AUTOSAR XML (schema 4-0-3)
standard types defined: Boolean, UInt16, UInt32
package /AUTOSAR_Platform/DataConstrs
  range DC_Boolean: raw 0..1
  range DC_UInt16: raw 0..65535
package /PATAC/Facility/DataTypes/Implementation
  compu method COMPU_Boolean: 0=FALSE, 1=TRUE
  unit NoUnit: factor-si-to-unit=1, offset-si-to-unit=0
package /PATAC/MSM/ComponentTypes
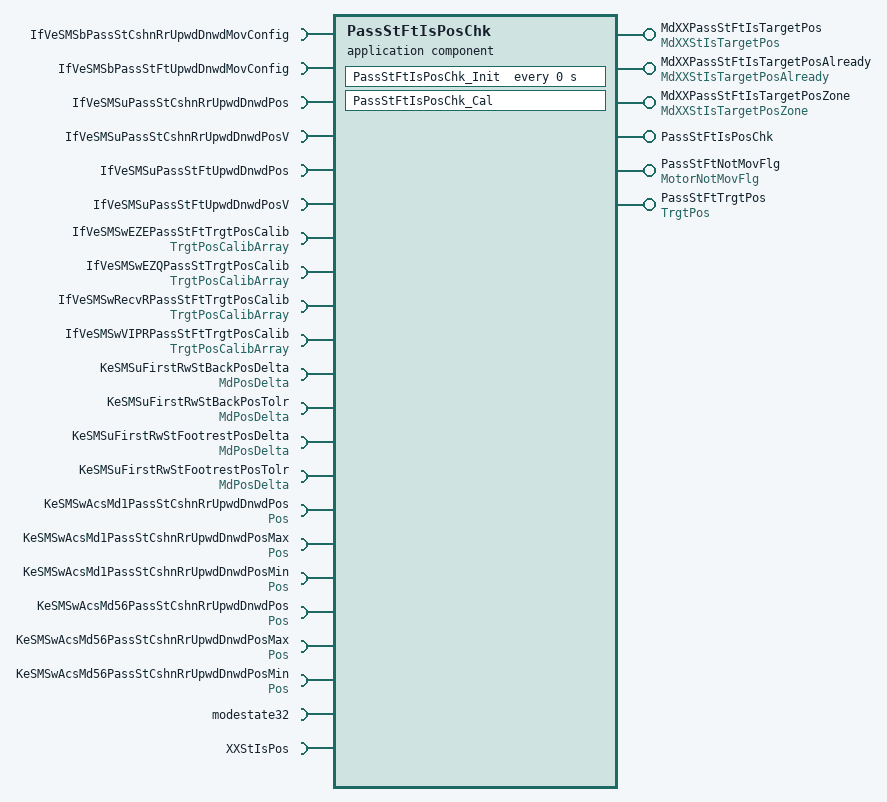
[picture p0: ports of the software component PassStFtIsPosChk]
  application sw component type PassStFtIsPosChk
    6 x provide port:
      MdXXPassStFtIsTargetPos: nonqueued-sender-com-spec{data-element=MdXXStIsTargetPos/Val, init-value=0}, provided-interface=MdXXStIsTargetPos
      MdXXPassStFtIsTargetPosAlready: nonqueued-sender-com-spec{data-element=MdXXStIsTargetPosAlready/Val, init-value=0}, provided-interface=MdXXStIsTargetPosAlready
      MdXXPassStFtIsTargetPosZone: nonqueued-sender-com-spec=data-element=MdXXStIsTargetPosZone/Val, provided-interface=MdXXStIsTargetPosZone
      PassStFtIsPosChk: server-com-spec{operation=Cal, queue-length=1}, provided-interface=PassStFtIsPosChk
      PassStFtNotMovFlg: nonqueued-sender-com-spec{data-element=MotorNotMovFlg/Val, init-value=0}, provided-interface=MotorNotMovFlg
      PassStFtTrgtPos: nonqueued-sender-com-spec{data-element=TrgtPos/Val, init-value=4095}, provided-interface=TrgtPos
    22 x require port:
      IfVeSMSbPassStCshnRrUpwdDnwdMovConfig: nonqueued-receiver-com-spec{data-element=IfVeSMSbPassStCshnRrUpwdDnwdMovConfig/Val, filter=data-filter-type=ALWAYS}, required-interface=IfVeSMSbPassStCshnRrUpwdDnwdMovConfig
      IfVeSMSbPassStFtUpwdDnwdMovConfig: nonqueued-receiver-com-spec{data-element=IfVeSMSbPassStFtUpwdDnwdMovConfig/Val, filter=data-filter-type=ALWAYS, init-value=0}, required-interface=IfVeSMSbPassStFtUpwdDnwdMovConfig
      IfVeSMSuPassStCshnRrUpwdDnwdPos: nonqueued-receiver-com-spec{data-element=IfVeSMSuPassStCshnRrUpwdDnwdPos/Val, filter=data-filter-type=ALWAYS}, required-interface=IfVeSMSuPassStCshnRrUpwdDnwdPos
      IfVeSMSuPassStCshnRrUpwdDnwdPosV: nonqueued-receiver-com-spec{data-element=IfVeSMSuPassStCshnRrUpwdDnwdPosV/Val, filter=data-filter-type=ALWAYS}, required-interface=IfVeSMSuPassStCshnRrUpwdDnwdPosV
      IfVeSMSuPassStFtUpwdDnwdPos: nonqueued-receiver-com-spec{data-element=IfVeSMSuPassStFtUpwdDnwdPos/Val, filter=data-filter-type=ALWAYS, init-value=0}, required-interface=IfVeSMSuPassStFtUpwdDnwdPos
      IfVeSMSuPassStFtUpwdDnwdPosV: nonqueued-receiver-com-spec{data-element=IfVeSMSuPassStFtUpwdDnwdPosV/Val, filter=data-filter-type=ALWAYS, init-value=0}, required-interface=IfVeSMSuPassStFtUpwdDnwdPosV
      IfVeSMSwEZEPassStFtTrgtPosCalib: nonqueued-receiver-com-spec{data-element=TrgtPosArray, filter=data-filter-type=ALWAYS, init-value=[4095, 4095, 4095]}, required-interface=TrgtPosCalibArray
      IfVeSMSwEZQPassStTrgtPosCalib: nonqueued-receiver-com-spec{data-element=TrgtPosArray, filter=data-filter-type=ALWAYS, init-value=[4095, 4095, 4095]}, required-interface=TrgtPosCalibArray
      IfVeSMSwRecvRPassStFtTrgtPosCalib: nonqueued-receiver-com-spec{data-element=TrgtPosArray, filter=data-filter-type=ALWAYS, init-value=[4095, 4095, 4095]}, required-interface=TrgtPosCalibArray
      IfVeSMSwVIPRPassStFtTrgtPosCalib: nonqueued-receiver-com-spec{data-element=TrgtPosArray, filter=data-filter-type=ALWAYS, init-value=[4095, 4095, 4095]}, required-interface=TrgtPosCalibArray
      KeSMSuFirstRwStBackPosDelta: parameter-require-com-spec{init-value=150, parameter=MdPosDelta/Val}, required-interface=MdPosDelta
      KeSMSuFirstRwStBackPosTolr: parameter-require-com-spec{init-value=150, parameter=MdPosDelta/Val}, required-interface=MdPosDelta
      KeSMSuFirstRwStFootrestPosDelta: parameter-require-com-spec{init-value=150, parameter=MdPosDelta/Val}, required-interface=MdPosDelta
      KeSMSuFirstRwStFootrestPosTolr: parameter-require-com-spec{init-value=150, parameter=MdPosDelta/Val}, required-interface=MdPosDelta
      KeSMSwAcsMd1PassStCshnRrUpwdDnwdPos: parameter-require-com-spec{init-value=0, parameter=Pos/Val}, required-interface=Pos
      KeSMSwAcsMd1PassStCshnRrUpwdDnwdPosMax: parameter-require-com-spec{init-value=0, parameter=Pos/Val}, required-interface=Pos
      KeSMSwAcsMd1PassStCshnRrUpwdDnwdPosMin: parameter-require-com-spec{init-value=0, parameter=Pos/Val}, required-interface=Pos
      KeSMSwAcsMd56PassStCshnRrUpwdDnwdPos: parameter-require-com-spec{init-value=0, parameter=Pos/Val}, required-interface=Pos
      KeSMSwAcsMd56PassStCshnRrUpwdDnwdPosMax: parameter-require-com-spec{init-value=0, parameter=Pos/Val}, required-interface=Pos
      KeSMSwAcsMd56PassStCshnRrUpwdDnwdPosMin: parameter-require-com-spec{init-value=0, parameter=Pos/Val}, required-interface=Pos
      modestate32: nonqueued-receiver-com-spec{data-element=modestate32/Val, filter=data-filter-type=ALWAYS, init-value=0}, required-interface=modestate32
      XXStIsPos: client-com-spec=Get, required-interface=XXStIsPos
    behavior PassStFtIsPosChk_InternalBehavior
      operation invoked event OIT_PassStFtIsPosChk_Cal_PassStFtIsPosChk_Cal: start-on-event=PassStFtIsPosChk_Cal, operation=PassStFtIsPosChk.Cal
      timing event PassStFtIsPosChk_InitEvent: start-on-event=PassStFtIsPosChk_Init, period=0
      runnable PassStFtIsPosChk_Cal
        data-receive-point-by-arguments:
          11 x access:
            REC_IfVeSMSbPassStCshnRrUpwdDnwdMovConfig_Val: accessed-variable=IfVeSMSbPassStCshnRrUpwdDnwdMovConfig.Val
            REC_IfVeSMSbPassStFtUpwdDnwdMovConfig_Val: accessed-variable=IfVeSMSbPassStFtUpwdDnwdMovConfig.Val
            REC_IfVeSMSuPassStCshnRrUpwdDnwdPos_Val: accessed-variable=IfVeSMSuPassStCshnRrUpwdDnwdPos.Val
            REC_IfVeSMSuPassStCshnRrUpwdDnwdPosV_Val: accessed-variable=IfVeSMSuPassStCshnRrUpwdDnwdPosV.Val
            REC_IfVeSMSuPassStFtUpwdDnwdPos_Val: accessed-variable=IfVeSMSuPassStFtUpwdDnwdPos.Val
            REC_IfVeSMSuPassStFtUpwdDnwdPosV_Val: accessed-variable=IfVeSMSuPassStFtUpwdDnwdPosV.Val
            REC_IfVeSMSwEZEPassStFtTrgtPosCalib_TrgtPosArray: accessed-variable=IfVeSMSwEZEPassStFtTrgtPosCalib.TrgtPosArray
            REC_IfVeSMSwEZQPassStTrgtPosCalib_TrgtPosArray: accessed-variable=IfVeSMSwEZQPassStTrgtPosCalib.TrgtPosArray
            REC_IfVeSMSwRecvRPassStFtTrgtPosCalib_TrgtPosArray: accessed-variable=IfVeSMSwRecvRPassStFtTrgtPosCalib.TrgtPosArray
            REC_IfVeSMSwVIPRPassStFtTrgtPosCalib_TrgtPosArray: accessed-variable=IfVeSMSwVIPRPassStFtTrgtPosCalib.TrgtPosArray
            REC_modestate32_Val: accessed-variable=modestate32.Val
        data-send-points:
          5 x access:
            SEND_MdXXPassStFtIsTargetPos_Val: accessed-variable=MdXXPassStFtIsTargetPos.Val
            SEND_MdXXPassStFtIsTargetPosAlready_Val: accessed-variable=MdXXPassStFtIsTargetPosAlready.Val
            SEND_MdXXPassStFtIsTargetPosZone_Val: accessed-variable=MdXXPassStFtIsTargetPosZone.Val
            SEND_PassStFtNotMovFlg_Val: accessed-variable=PassStFtNotMovFlg.Val
            SEND_PassStFtTrgtPos_Val: accessed-variable=PassStFtTrgtPos.Val
        10 x parameter access:
          PA_KeSMSuFirstRwStBackPosDelta_Val: accessed-parameter=KeSMSuFirstRwStBackPosDelta.Val
          PA_KeSMSuFirstRwStBackPosTolr_Val: accessed-parameter=KeSMSuFirstRwStBackPosTolr.Val
          PA_KeSMSuFirstRwStFootrestPosDelta_Val: accessed-parameter=KeSMSuFirstRwStFootrestPosDelta.Val
          PA_KeSMSuFirstRwStFootrestPosTolr_Val: accessed-parameter=KeSMSuFirstRwStFootrestPosTolr.Val
          PA_KeSMSwAcsMd1PassStCshnRrUpwdDnwdPos_Val: accessed-parameter=KeSMSwAcsMd1PassStCshnRrUpwdDnwdPos.Val
          PA_KeSMSwAcsMd1PassStCshnRrUpwdDnwdPosMax_Val: accessed-parameter=KeSMSwAcsMd1PassStCshnRrUpwdDnwdPosMax.Val
          PA_KeSMSwAcsMd1PassStCshnRrUpwdDnwdPosMin_Val: accessed-parameter=KeSMSwAcsMd1PassStCshnRrUpwdDnwdPosMin.Val
          PA_KeSMSwAcsMd56PassStCshnRrUpwdDnwdPos_Val: accessed-parameter=KeSMSwAcsMd56PassStCshnRrUpwdDnwdPos.Val
          PA_KeSMSwAcsMd56PassStCshnRrUpwdDnwdPosMax_Val: accessed-parameter=KeSMSwAcsMd56PassStCshnRrUpwdDnwdPosMax.Val
          PA_KeSMSwAcsMd56PassStCshnRrUpwdDnwdPosMin_Val: accessed-parameter=KeSMSwAcsMd56PassStCshnRrUpwdDnwdPosMin.Val
        sync call SC_XXStIsPos_Get: operation=XXStIsPos.Get, timeout=0
      runnable PassStFtIsPosChk_Init
        10 x parameter access:
          PA_KeSMSuFirstRwStBackPosDelta_Val: accessed-parameter=KeSMSuFirstRwStBackPosDelta.Val
          PA_KeSMSuFirstRwStBackPosTolr_Val: accessed-parameter=KeSMSuFirstRwStBackPosTolr.Val
          PA_KeSMSuFirstRwStFootrestPosDelta_Val: accessed-parameter=KeSMSuFirstRwStFootrestPosDelta.Val
          PA_KeSMSuFirstRwStFootrestPosTolr_Val: accessed-parameter=KeSMSuFirstRwStFootrestPosTolr.Val
          PA_KeSMSwAcsMd1PassStCshnRrUpwdDnwdPos_Val: accessed-parameter=KeSMSwAcsMd1PassStCshnRrUpwdDnwdPos.Val
          PA_KeSMSwAcsMd1PassStCshnRrUpwdDnwdPosMax_Val: accessed-parameter=KeSMSwAcsMd1PassStCshnRrUpwdDnwdPosMax.Val
          PA_KeSMSwAcsMd1PassStCshnRrUpwdDnwdPosMin_Val: accessed-parameter=KeSMSwAcsMd1PassStCshnRrUpwdDnwdPosMin.Val
          PA_KeSMSwAcsMd56PassStCshnRrUpwdDnwdPos_Val: accessed-parameter=KeSMSwAcsMd56PassStCshnRrUpwdDnwdPos.Val
          PA_KeSMSwAcsMd56PassStCshnRrUpwdDnwdPosMax_Val: accessed-parameter=KeSMSwAcsMd56PassStCshnRrUpwdDnwdPosMax.Val
          PA_KeSMSwAcsMd56PassStCshnRrUpwdDnwdPosMin_Val: accessed-parameter=KeSMSwAcsMd56PassStCshnRrUpwdDnwdPosMin.Val
  swc implementation PassStFtIsPosChk_Implementation: behavior=PassStFtIsPosChk_InternalBehavior
    code-descriptors:
      code Default: artifact-descriptors=autosar-engineering-object={short-label=Default, category=SWSRC}
package /PATAC/MSM/ModeAdjust/CalPortInterface
  parameter interface MdPosDelta
    parameter data prototype Val: sw-calibration-access=READ-WRITE, type=UInt16
  parameter interface Pos
    parameter data prototype Val: sw-calibration-access=READ-WRITE, type=UInt16
package /PATAC/MSM/ModeAdjust/DataType
  impl type TrgtPosCalibArray: category=ARRAY, sw-calibration-access=READ-ONLY, type-emitter=RTE  # 0:pos 1:max 2:min
    element Element: array-size=3, array-size-semantics=FIXED-SIZE, implementation-data-type=UInt16, invalid-value=0
package /PATAC/MSM/ModeAdjust/Interfaces
  sender receiver interface IfVeSMSuPassStCshnRrUpwdDnwdPosV: invalidation-policy{data-element=IfVeSMSuPassStCshnRrUpwdDnwdPosV/Val, handle-invalid=DONT-INVALIDATE}
    data Val: type=Implementation/Boolean
  sender receiver interface IfVeSMSuPassStFtUpwdDnwdPosV: invalidation-policy{data-element=IfVeSMSuPassStFtUpwdDnwdPosV/Val, handle-invalid=DONT-INVALIDATE}
    data Val: type=Implementation/Boolean
package /PATAC/MSM/ModeAdjust/PortInterface
  client server interface PassStFtIsPosChk
    operation Cal
  client server interface XXStIsPos
    operation Get
      8 x arg, all with server-argument-impl-policy=USE-ARGUMENT-TYPE:
        PosV: type=DataTypes/Boolean, direction=IN
        Pos: type=UInt16, direction=IN
        CalibArray: type=TrgtPosCalibArray, direction=IN
        Delta: type=UInt16, direction=IN
        Tolr: type=UInt16, direction=IN
        IsPos: type=DataTypes/Boolean, direction=OUT
        IsPosZone: type=DataTypes/Boolean, direction=OUT
        IsPosAlready: type=DataTypes/Boolean, direction=OUT
  6 x sender receiver interface:
    MdXXStIsTargetPos: invalidation-policy{data-element=MdXXStIsTargetPos/Val, handle-invalid=DONT-INVALIDATE}
      data Val: type=UInt32
    MdXXStIsTargetPosAlready: invalidation-policy{data-element=MdXXStIsTargetPosAlready/Val, handle-invalid=DONT-INVALIDATE}
      data Val: type=UInt32
    MdXXStIsTargetPosZone: invalidation-policy{data-element=MdXXStIsTargetPosZone/Val, handle-invalid=DONT-INVALIDATE}
      data Val: type=UInt32
    modestate32: invalidation-policy{data-element=modestate32/Val, handle-invalid=DONT-INVALIDATE}
      data Val: type=UInt32
    MotorNotMovFlg: invalidation-policy{data-element=MotorNotMovFlg/Val, handle-invalid=DONT-INVALIDATE}
      data Val: type=Implementation/Boolean
    TrgtPosCalibArray: invalidation-policy{data-element=TrgtPosArray, handle-invalid=DONT-INVALIDATE}
      data TrgtPosArray: type=TrgtPosCalibArray  # 0:Pos 1:Max 2:Min
package /PATAC/MSM/PortInterfaces
  5 x sender receiver interface:
    IfVeSMSbPassStCshnRrUpwdDnwdMovConfig: invalidation-policy{data-element=IfVeSMSbPassStCshnRrUpwdDnwdMovConfig/Val, handle-invalid=DONT-INVALIDATE}
      data Val: type=Implementation/Boolean
    IfVeSMSbPassStFtUpwdDnwdMovConfig: invalidation-policy{data-element=IfVeSMSbPassStFtUpwdDnwdMovConfig/Val, handle-invalid=DONT-INVALIDATE}
      data Val: type=Implementation/Boolean
    IfVeSMSuPassStCshnRrUpwdDnwdPos: invalidation-policy{data-element=IfVeSMSuPassStCshnRrUpwdDnwdPos/Val, handle-invalid=DONT-INVALIDATE}
      data Val: type=UInt16
    IfVeSMSuPassStFtUpwdDnwdPos: invalidation-policy{data-element=IfVeSMSuPassStFtUpwdDnwdPos/Val, handle-invalid=DONT-INVALIDATE}
      data Val: type=UInt16
    TrgtPos: invalidation-policy{data-element=TrgtPos/Val, handle-invalid=DONT-INVALIDATE}
      data Val: type=UInt16
